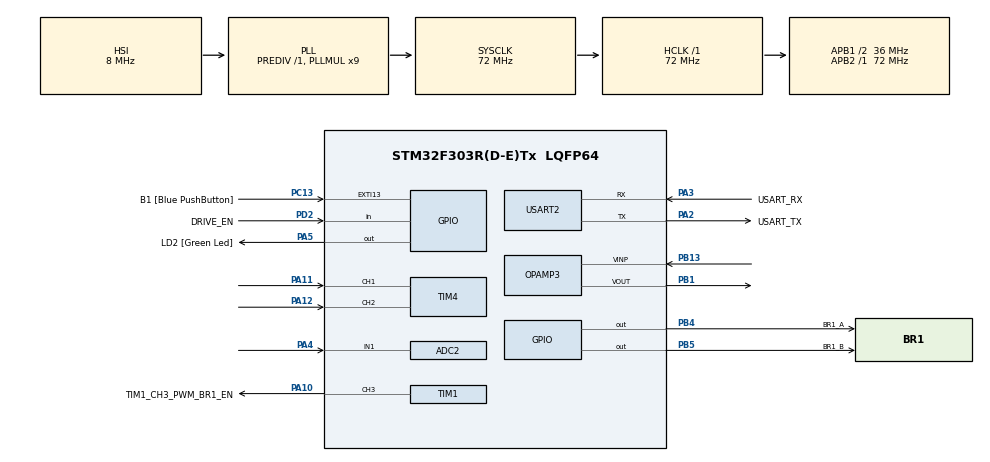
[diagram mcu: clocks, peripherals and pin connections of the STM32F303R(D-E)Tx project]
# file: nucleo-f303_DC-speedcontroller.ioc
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Mcu.Family=STM32F3
NVIC.ADC1_2_IRQn=true\:0\:0\:false\:false\:true\:true\:true
PA2.GPIO_PuPd=GPIO_NOPULL
VP_SYS_VS_tim6.Mode=TIM6
RCC.CortexFreq_Value=72000000
ADC2.SamplingTime-1\#ChannelRegularConversion=ADC_SAMPLETIME_1CYCLE_5
NVIC.TIM6_DAC_IRQn=true\:0\:0\:false\:false\:true\:false\:true
PA14.GPIO_Label=TCK
RCC.SYSCLKSourceVirtual=RCC_SYSCLKSOURCE_PLLCLK
PA3.GPIO_PuPd=GPIO_NOPULL
PA2.GPIO_Speed=GPIO_SPEED_FREQ_LOW
PC13.GPIO_Label=B1 [Blue PushButton]
PA3.GPIO_Speed=GPIO_SPEED_FREQ_LOW
PB13.Signal=OPAMP3_VINP
ADC3.Channel-0\#ChannelRegularConversion=ADC_CHANNEL_VOPAMP3
ProjectManager.StackSize=0x400
ADC2.SamplingTimeOPAMP-1\#ChannelRegularConversion=ADC_SAMPLETIME_61CYCLES_5
PA12.Signal=S_TIM4_CH2
PA4.Mode=IN1-Single-Ended
RCC.HCLKFreq_Value=72000000
RCC.APB2TimFreq_Value=72000000
RCC.AHBFreq_Value=72000000
RCC.HSE_VALUE=8000000
USART2.VirtualMode-Asynchronous=VM_ASYNC
RCC.RCC_PLLsource_Clock_Source_FROM_HSE=RCC_HSE_PREDIV_DIV2
RCC.PLLMUL=RCC_PLL_MUL9
PC14-OSC32_IN.Mode=LSE-External-Oscillator
PA14.Mode=Serial_Wire
PA5.GPIO_PuPd=GPIO_NOPULL
PA10.GPIO_Label=TIM1_CH3_PWM_BR1_EN
SH.S_TIM4_CH2.0=TIM4_CH2,Encoder_Interface
ADC3.master=1
Mcu.Package=LQFP64
PB1.Signal=OPAMP3_VOUT
PA6.Signal=ADC2_IN3
NVIC.TimeBase=TIM6_DAC_IRQn
PA2.GPIO_Label=USART_TX
ADC2.Channel-1\#ChannelRegularConversion=ADC_CHANNEL_1
ADC3.Rank-0\#ChannelRegularConversion=1
NVIC.TimeBaseIP=TIM6
PA10.Signal=S_TIM1_CH3
ADC3.OffsetNumber-0\#ChannelRegularConversion=ADC_OFFSET_NONE
PB5.GPIO_Label=BR1_B
SH.S_TIM4_CH1.0=TIM4_CH1,Encoder_Interface
RCC.APB1TimFreq_Value=72000000
PB13.Mode=PGA Not Connected
PF1-OSC_OUT.Signal=RCC_OSC_OUT
PB4.Signal=GPIO_Output
PA3.Signal=USART2_RX
PA2.GPIO_Mode=GPIO_MODE_AF_PP
PB3.GPIO_Label=SWO
PC15-OSC32_OUT.Mode=LSE-External-Oscillator
PC13.Signal=GPXTI13
RCC.APB1CLKDivider=RCC_HCLK_DIV2
PC14-OSC32_IN.Signal=RCC_OSC32_IN
PA13.Signal=SYS_JTMS-SWDIO
PA3.Mode=Asynchronous
ADC3.SamplingTime-0\#ChannelRegularConversion=ADC_SAMPLETIME_61CYCLES_5
ProjectManager.TargetToolchain=STM32CubeIDE
PA3.GPIO_Mode=GPIO_MODE_AF_PP
ADC3.SamplingTimeOPAMP-0\#ChannelRegularConversion=ADC_SAMPLETIME_61CYCLES_5
RCC.USBFreq_Value=72000000
PC15-OSC32_OUT.Signal=RCC_OSC32_OUT
PF0-OSC_IN.Mode=HSE-External-Clock-Source
ADC2.OffsetNumber-1\#ChannelRegularConversion=ADC_OFFSET_NONE
PB10.Signal=OPAMP3_VINM
PA5.Signal=GPIO_Output
board=NUCLEO-F303RE
ADC2.Offset-1\#ChannelRegularConversion=0
RCC.APB2Freq_Value=72000000
PB4.GPIO_Label=BR1_A
PA13.Mode=Serial_Wire
Mcu.Name=STM32F303R(D-E)Tx
PA2.Signal=USART2_TX
PA13.GPIO_Label=TMS
VP_ADC3_OPAMP_INTERNAL3.Mode=IN-OPAMP3
PB3.Signal=SYS_JTDO-TRACESWO
PA4.Signal=ADC2_IN1
RCC.SYSCLKFreq_VALUE=72000000
PB5.Signal=GPIO_Output
PA5.GPIO_Label=LD2 [Green Led]
ADC2.NbrOfConversionFlag=1
PC13.GPIO_ModeDefaultEXTI=GPIO_MODE_IT_FALLING
PA11.Signal=S_TIM4_CH1
PA14.Signal=SYS_JTCK-SWCLK
ProjectManager.HeapSize=0x200
PB1.Mode=PGA Not Connected
SH.S_TIM1_CH3.0=TIM1_CH3,PWM Generation3 CH3
RCC.HSI_VALUE=8000000
ADC3.Offset-0\#ChannelRegularConversion=0
RCC.PLLP=RCC_PLLP_DIV4
PA5.GPIO_Speed=GPIO_SPEED_FREQ_LOW
RCC.PLLQ=7
NVIC.PriorityGroup=NVIC_PRIORITYGROUP_0
RCC.PLLM=8
RCC.PLLN=336
ADC2.Rank-1\#ChannelRegularConversion=1
PA2.Mode=Asynchronous
PF0-OSC_IN.Signal=RCC_OSC_IN
TIM1.Channel-PWM\ Generation3\ CH3=TIM_CHANNEL_3
PD2.Signal=GPIO_Input
RCC.APB1Freq_Value=36000000
PA5.GPIO_Mode=GPIO_MODE_OUTPUT_PP
ADC3.NbrOfConversionFlag=1
PD2.GPIO_Label=DRIVE_EN
PA3.GPIO_Label=USART_RX

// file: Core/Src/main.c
/* USER CODE BEGIN Header */
/**
  ******************************************************************************
  * @file           : main.c
  * @brief          : Main program body
  ******************************************************************************
  * @attention
  *
  * <h2><center>&copy; Copyright (c) 2021 STMicroelectronics.
  * All rights reserved.</center></h2>
  *
  * This software component is licensed by ST under BSD 3-Clause license,
  * the "License"; You may not use this file except in compliance with the
  * License. You may obtain a copy of the License at:
  *                        opensource.org/licenses/BSD-3-Clause
  *
  ******************************************************************************
  */
/* USER CODE END Header */
#include "main.h"

/* USER CODE BEGIN Includes */
#include "controller_functions.h"
/* USER CODE END Includes */

ADC_HandleTypeDef hadc2;
ADC_HandleTypeDef hadc3;

OPAMP_HandleTypeDef hopamp3;

TIM_HandleTypeDef htim1;
TIM_HandleTypeDef htim4;

UART_HandleTypeDef huart2;

/* USER CODE BEGIN PV */

arm_pid_instance_f32 speedctrl;

/* USER CODE END PV */

void SystemClock_Config(void);
static void MX_GPIO_Init(void);
static void MX_USART2_UART_Init(void);
static void MX_ADC2_Init(void);
static void MX_ADC3_Init(void);
static void MX_OPAMP3_Init(void);
static void MX_TIM1_Init(void);
static void MX_TIM4_Init(void);

int main(void)
{

  /* MCU Configuration--------------------------------------------------------*/

  /* Reset of all peripherals, Initializes the Flash interface and the Systick. */
  HAL_Init();

  /* Configure the system clock */
  SystemClock_Config();

  /* Initialize all configured peripherals */
  MX_GPIO_Init();
  MX_USART2_UART_Init();
  MX_ADC2_Init();
  MX_ADC3_Init();
  MX_OPAMP3_Init();
  MX_TIM1_Init();
  MX_TIM4_Init();

  /* Infinite loop */
  while (1)
  {

  }
}

void SystemClock_Config(void)
{
  RCC_OscInitTypeDef RCC_OscInitStruct = {0};
  RCC_ClkInitTypeDef RCC_ClkInitStruct = {0};
  RCC_PeriphCLKInitTypeDef PeriphClkInit = {0};

  /** Initializes the RCC Oscillators according to the specified parameters
  * in the RCC_OscInitTypeDef structure.
  */
  RCC_OscInitStruct.OscillatorType = RCC_OSCILLATORTYPE_HSI;
  RCC_OscInitStruct.HSIState = RCC_HSI_ON;
  RCC_OscInitStruct.HSICalibrationValue = RCC_HSICALIBRATION_DEFAULT;
  RCC_OscInitStruct.PLL.PLLState = RCC_PLL_ON;
  RCC_OscInitStruct.PLL.PLLSource = RCC_PLLSOURCE_HSI;
  RCC_OscInitStruct.PLL.PLLMUL = RCC_PLL_MUL9;
  RCC_OscInitStruct.PLL.PREDIV = RCC_PREDIV_DIV1;
  if (HAL_RCC_OscConfig(&RCC_OscInitStruct) != HAL_OK)
  {
    Error_Handler();
  }
  /** Initializes the CPU, AHB and APB buses clocks
  */
  RCC_ClkInitStruct.ClockType = RCC_CLOCKTYPE_HCLK|RCC_CLOCKTYPE_SYSCLK
                              |RCC_CLOCKTYPE_PCLK1|RCC_CLOCKTYPE_PCLK2;
  RCC_ClkInitStruct.SYSCLKSource = RCC_SYSCLKSOURCE_PLLCLK;
  RCC_ClkInitStruct.AHBCLKDivider = RCC_SYSCLK_DIV1;
  RCC_ClkInitStruct.APB1CLKDivider = RCC_HCLK_DIV2;
  RCC_ClkInitStruct.APB2CLKDivider = RCC_HCLK_DIV1;

  if (HAL_RCC_ClockConfig(&RCC_ClkInitStruct, FLASH_LATENCY_2) != HAL_OK)
  {
    Error_Handler();
  }
  PeriphClkInit.PeriphClockSelection = RCC_PERIPHCLK_USART2|RCC_PERIPHCLK_TIM1
                              |RCC_PERIPHCLK_ADC12|RCC_PERIPHCLK_ADC34
                              |RCC_PERIPHCLK_TIM34;
  PeriphClkInit.Usart2ClockSelection = RCC_USART2CLKSOURCE_PCLK1;
  PeriphClkInit.Adc12ClockSelection = RCC_ADC12PLLCLK_DIV1;
  PeriphClkInit.Adc34ClockSelection = RCC_ADC34PLLCLK_DIV1;
  PeriphClkInit.Tim1ClockSelection = RCC_TIM1CLK_HCLK;
  PeriphClkInit.Tim34ClockSelection = RCC_TIM34CLK_HCLK;
  if (HAL_RCCEx_PeriphCLKConfig(&PeriphClkInit) != HAL_OK)
  {
    Error_Handler();
  }
}

static void MX_ADC2_Init(void)
{

  ADC_ChannelConfTypeDef sConfig = {0};

  /** Common config
  */
  hadc2.Instance = ADC2;
  hadc2.Init.ClockPrescaler = ADC_CLOCK_ASYNC_DIV1;
  hadc2.Init.Resolution = ADC_RESOLUTION_12B;
  hadc2.Init.ScanConvMode = ADC_SCAN_DISABLE;
  hadc2.Init.ContinuousConvMode = DISABLE;
  hadc2.Init.DiscontinuousConvMode = DISABLE;
  hadc2.Init.ExternalTrigConvEdge = ADC_EXTERNALTRIGCONVEDGE_NONE;
  hadc2.Init.ExternalTrigConv = ADC_SOFTWARE_START;
  hadc2.Init.DataAlign = ADC_DATAALIGN_RIGHT;
  hadc2.Init.NbrOfConversion = 1;
  hadc2.Init.DMAContinuousRequests = DISABLE;
  hadc2.Init.EOCSelection = ADC_EOC_SINGLE_CONV;
  hadc2.Init.LowPowerAutoWait = DISABLE;
  hadc2.Init.Overrun = ADC_OVR_DATA_OVERWRITTEN;
  if (HAL_ADC_Init(&hadc2) != HAL_OK)
  {
    Error_Handler();
  }
  /** Configure Regular Channel
  */
  sConfig.Channel = ADC_CHANNEL_1;
  sConfig.Rank = ADC_REGULAR_RANK_1;
  sConfig.SingleDiff = ADC_SINGLE_ENDED;
  sConfig.SamplingTime = ADC_SAMPLETIME_1CYCLE_5;
  sConfig.OffsetNumber = ADC_OFFSET_NONE;
  sConfig.Offset = 0;
  if (HAL_ADC_ConfigChannel(&hadc2, &sConfig) != HAL_OK)
  {
    Error_Handler();
  }

}

static void MX_ADC3_Init(void)
{

  ADC_MultiModeTypeDef multimode = {0};
  ADC_ChannelConfTypeDef sConfig = {0};

  /** Common config
  */
  hadc3.Instance = ADC3;
  hadc3.Init.ClockPrescaler = ADC_CLOCK_ASYNC_DIV1;
  hadc3.Init.Resolution = ADC_RESOLUTION_12B;
  hadc3.Init.ScanConvMode = ADC_SCAN_DISABLE;
  hadc3.Init.ContinuousConvMode = DISABLE;
  hadc3.Init.DiscontinuousConvMode = DISABLE;
  hadc3.Init.ExternalTrigConvEdge = ADC_EXTERNALTRIGCONVEDGE_NONE;
  hadc3.Init.ExternalTrigConv = ADC_SOFTWARE_START;
  hadc3.Init.DataAlign = ADC_DATAALIGN_RIGHT;
  hadc3.Init.NbrOfConversion = 1;
  hadc3.Init.DMAContinuousRequests = DISABLE;
  hadc3.Init.EOCSelection = ADC_EOC_SINGLE_CONV;
  hadc3.Init.LowPowerAutoWait = DISABLE;
  hadc3.Init.Overrun = ADC_OVR_DATA_OVERWRITTEN;
  if (HAL_ADC_Init(&hadc3) != HAL_OK)
  {
    Error_Handler();
  }
  /** Configure the ADC multi-mode
  */
  multimode.Mode = ADC_MODE_INDEPENDENT;
  if (HAL_ADCEx_MultiModeConfigChannel(&hadc3, &multimode) != HAL_OK)
  {
    Error_Handler();
  }
  /** Configure Regular Channel
  */
  sConfig.Channel = ADC_CHANNEL_VOPAMP3;
  sConfig.Rank = ADC_REGULAR_RANK_1;
  sConfig.SingleDiff = ADC_SINGLE_ENDED;
  sConfig.SamplingTime = ADC_SAMPLETIME_61CYCLES_5;
  sConfig.OffsetNumber = ADC_OFFSET_NONE;
  sConfig.Offset = 0;
  if (HAL_ADC_ConfigChannel(&hadc3, &sConfig) != HAL_OK)
  {
    Error_Handler();
  }

}

static void MX_OPAMP3_Init(void)
{

  hopamp3.Instance = OPAMP3;
  hopamp3.Init.Mode = OPAMP_PGA_MODE;
  hopamp3.Init.NonInvertingInput = OPAMP_NONINVERTINGINPUT_IO1;
  hopamp3.Init.TimerControlledMuxmode = OPAMP_TIMERCONTROLLEDMUXMODE_DISABLE;
  hopamp3.Init.PgaConnect = OPAMP_PGA_CONNECT_INVERTINGINPUT_NO;
  hopamp3.Init.PgaGain = OPAMP_PGA_GAIN_2;
  hopamp3.Init.UserTrimming = OPAMP_TRIMMING_FACTORY;
  if (HAL_OPAMP_Init(&hopamp3) != HAL_OK)
  {
    Error_Handler();
  }

}

static void MX_TIM1_Init(void)
{

  TIM_MasterConfigTypeDef sMasterConfig = {0};
  TIM_OC_InitTypeDef sConfigOC = {0};
  TIM_BreakDeadTimeConfigTypeDef sBreakDeadTimeConfig = {0};

  htim1.Instance = TIM1;
  htim1.Init.Prescaler = 0;
  htim1.Init.CounterMode = TIM_COUNTERMODE_UP;
  htim1.Init.Period = 65535;
  htim1.Init.ClockDivision = TIM_CLOCKDIVISION_DIV1;
  htim1.Init.RepetitionCounter = 0;
  htim1.Init.AutoReloadPreload = TIM_AUTORELOAD_PRELOAD_DISABLE;
  if (HAL_TIM_PWM_Init(&htim1) != HAL_OK)
  {
    Error_Handler();
  }
  sMasterConfig.MasterOutputTrigger = TIM_TRGO_RESET;
  sMasterConfig.MasterOutputTrigger2 = TIM_TRGO2_RESET;
  sMasterConfig.MasterSlaveMode = TIM_MASTERSLAVEMODE_DISABLE;
  if (HAL_TIMEx_MasterConfigSynchronization(&htim1, &sMasterConfig) != HAL_OK)
  {
    Error_Handler();
  }
  sConfigOC.OCMode = TIM_OCMODE_PWM1;
  sConfigOC.Pulse = 0;
  sConfigOC.OCPolarity = TIM_OCPOLARITY_HIGH;
  sConfigOC.OCNPolarity = TIM_OCNPOLARITY_HIGH;
  sConfigOC.OCFastMode = TIM_OCFAST_DISABLE;
  sConfigOC.OCIdleState = TIM_OCIDLESTATE_RESET;
  sConfigOC.OCNIdleState = TIM_OCNIDLESTATE_RESET;
  if (HAL_TIM_PWM_ConfigChannel(&htim1, &sConfigOC, TIM_CHANNEL_3) != HAL_OK)
  {
    Error_Handler();
  }
  sBreakDeadTimeConfig.OffStateRunMode = TIM_OSSR_DISABLE;
  sBreakDeadTimeConfig.OffStateIDLEMode = TIM_OSSI_DISABLE;
  sBreakDeadTimeConfig.LockLevel = TIM_LOCKLEVEL_OFF;
  sBreakDeadTimeConfig.DeadTime = 0;
  sBreakDeadTimeConfig.BreakState = TIM_BREAK_DISABLE;
  sBreakDeadTimeConfig.BreakPolarity = TIM_BREAKPOLARITY_HIGH;
  sBreakDeadTimeConfig.BreakFilter = 0;
  sBreakDeadTimeConfig.Break2State = TIM_BREAK2_DISABLE;
  sBreakDeadTimeConfig.Break2Polarity = TIM_BREAK2POLARITY_HIGH;
  sBreakDeadTimeConfig.Break2Filter = 0;
  sBreakDeadTimeConfig.AutomaticOutput = TIM_AUTOMATICOUTPUT_DISABLE;
  if (HAL_TIMEx_ConfigBreakDeadTime(&htim1, &sBreakDeadTimeConfig) != HAL_OK)
  {
    Error_Handler();
  }
  HAL_TIM_MspPostInit(&htim1);

}

static void MX_TIM4_Init(void)
{

  TIM_Encoder_InitTypeDef sConfig = {0};
  TIM_MasterConfigTypeDef sMasterConfig = {0};

  htim4.Instance = TIM4;
  htim4.Init.Prescaler = 0;
  htim4.Init.CounterMode = TIM_COUNTERMODE_UP;
  htim4.Init.Period = 65535;
  htim4.Init.ClockDivision = TIM_CLOCKDIVISION_DIV1;
  htim4.Init.AutoReloadPreload = TIM_AUTORELOAD_PRELOAD_DISABLE;
  sConfig.EncoderMode = TIM_ENCODERMODE_TI1;
  sConfig.IC1Polarity = TIM_ICPOLARITY_RISING;
  sConfig.IC1Selection = TIM_ICSELECTION_DIRECTTI;
  sConfig.IC1Prescaler = TIM_ICPSC_DIV1;
  sConfig.IC1Filter = 0;
  sConfig.IC2Polarity = TIM_ICPOLARITY_RISING;
  sConfig.IC2Selection = TIM_ICSELECTION_DIRECTTI;
  sConfig.IC2Prescaler = TIM_ICPSC_DIV1;
  sConfig.IC2Filter = 0;
  if (HAL_TIM_Encoder_Init(&htim4, &sConfig) != HAL_OK)
  {
    Error_Handler();
  }
  sMasterConfig.MasterOutputTrigger = TIM_TRGO_RESET;
  sMasterConfig.MasterSlaveMode = TIM_MASTERSLAVEMODE_DISABLE;
  if (HAL_TIMEx_MasterConfigSynchronization(&htim4, &sMasterConfig) != HAL_OK)
  {
    Error_Handler();
  }

}

static void MX_USART2_UART_Init(void)
{

  huart2.Instance = USART2;
  huart2.Init.BaudRate = 38400;
  huart2.Init.WordLength = UART_WORDLENGTH_8B;
  huart2.Init.StopBits = UART_STOPBITS_1;
  huart2.Init.Parity = UART_PARITY_NONE;
  huart2.Init.Mode = UART_MODE_TX_RX;
  huart2.Init.HwFlowCtl = UART_HWCONTROL_NONE;
  huart2.Init.OverSampling = UART_OVERSAMPLING_16;
  huart2.Init.OneBitSampling = UART_ONE_BIT_SAMPLE_DISABLE;
  huart2.AdvancedInit.AdvFeatureInit = UART_ADVFEATURE_NO_INIT;
  if (HAL_UART_Init(&huart2) != HAL_OK)
  {
    Error_Handler();
  }

}

static void MX_GPIO_Init(void)
{
  GPIO_InitTypeDef GPIO_InitStruct = {0};

  /* GPIO Ports Clock Enable */
  __HAL_RCC_GPIOC_CLK_ENABLE();
  __HAL_RCC_GPIOF_CLK_ENABLE();
  __HAL_RCC_GPIOA_CLK_ENABLE();
  __HAL_RCC_GPIOB_CLK_ENABLE();
  __HAL_RCC_GPIOD_CLK_ENABLE();

  /*Configure GPIO pin Output Level */
  HAL_GPIO_WritePin(LD2_GPIO_Port, LD2_Pin, GPIO_PIN_RESET);

  /*Configure GPIO pin Output Level */
  HAL_GPIO_WritePin(GPIOB, BR1_A_Pin|BR1_B_Pin, GPIO_PIN_RESET);

  /*Configure GPIO pin : B1_Pin */
  GPIO_InitStruct.Pin = B1_Pin;
  GPIO_InitStruct.Mode = GPIO_MODE_IT_FALLING;
  GPIO_InitStruct.Pull = GPIO_NOPULL;
  HAL_GPIO_Init(B1_GPIO_Port, &GPIO_InitStruct);

  /*Configure GPIO pin : LD2_Pin */
  GPIO_InitStruct.Pin = LD2_Pin;
  GPIO_InitStruct.Mode = GPIO_MODE_OUTPUT_PP;
  GPIO_InitStruct.Pull = GPIO_NOPULL;
  GPIO_InitStruct.Speed = GPIO_SPEED_FREQ_LOW;
  HAL_GPIO_Init(LD2_GPIO_Port, &GPIO_InitStruct);

  /*Configure GPIO pin : DRIVE_EN_Pin */
  GPIO_InitStruct.Pin = DRIVE_EN_Pin;
  GPIO_InitStruct.Mode = GPIO_MODE_INPUT;
  GPIO_InitStruct.Pull = GPIO_NOPULL;
  HAL_GPIO_Init(DRIVE_EN_GPIO_Port, &GPIO_InitStruct);

  /*Configure GPIO pins : BR1_A_Pin BR1_B_Pin */
  GPIO_InitStruct.Pin = BR1_A_Pin|BR1_B_Pin;
  GPIO_InitStruct.Mode = GPIO_MODE_OUTPUT_PP;
  GPIO_InitStruct.Pull = GPIO_NOPULL;
  GPIO_InitStruct.Speed = GPIO_SPEED_FREQ_LOW;
  HAL_GPIO_Init(GPIOB, &GPIO_InitStruct);

}

 /**
  * @brief  Period elapsed callback in non blocking mode
  * @note   This function is called  when TIM6 interrupt took place, inside
  * HAL_TIM_IRQHandler(). It makes a direct call to HAL_IncTick() to increment
  * a global variable "uwTick" used as application time base.
  * @param  htim : TIM handle
  * @retval None
  */
void HAL_TIM_PeriodElapsedCallback(TIM_HandleTypeDef *htim)
{
  if (htim->Instance == TIM6) {
    HAL_IncTick();
  }
}

void Error_Handler(void)
{
  __disable_irq();
  while (1)
  {
  }
}

/************************ (C) COPYRIGHT STMicroelectronics *****END OF FILE****/
